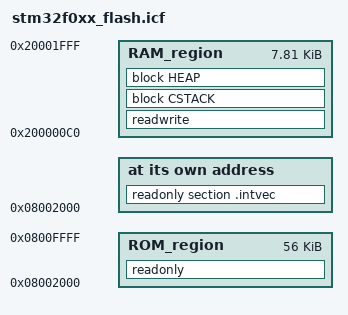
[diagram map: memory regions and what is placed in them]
/*-Specials-*/
define symbol __ICFEDIT_intvec_start__ = 0x08002000;
/*-Memory Regions-*/
/* The first part in flash is reserved for OpenBLT */
define symbol __ICFEDIT_region_ROM_start__ = 0x08002000 ;
define symbol __ICFEDIT_region_ROM_end__   = 0x0800FFFF;
/* The first 192 bytes in RAM are reserved for OpenBLT. Right before
 * starting this program, OpenBLT copies our interrupt vector table
 * to the start of RAM and remaps the RAM to also appear at address 
 * 0x00000000.
 */
define symbol __ICFEDIT_region_RAM_start__ = 0x200000C0;
define symbol __ICFEDIT_region_RAM_end__   = 0x20001FFF;
/*-Sizes-*/
define symbol __ICFEDIT_size_cstack__ = 0x400;
define symbol __ICFEDIT_size_heap__   = 0x200;


define memory mem with size = 4G;
define region ROM_region   = mem:[from __ICFEDIT_region_ROM_start__   to __ICFEDIT_region_ROM_end__];
define region RAM_region   = mem:[from __ICFEDIT_region_RAM_start__   to __ICFEDIT_region_RAM_end__];
export symbol __ICFEDIT_region_RAM_start__;
export symbol __ICFEDIT_region_RAM_end__;
define block CSTACK    with alignment = 8, size = __ICFEDIT_size_cstack__   { };
define block HEAP      with alignment = 8, size = __ICFEDIT_size_heap__     { };

initialize by copy { readwrite };
do not initialize  { section .noinit };

place at address mem:__ICFEDIT_intvec_start__ { readonly section .intvec };

place in ROM_region   { readonly };
place in RAM_region   { readwrite,
                        block CSTACK, block HEAP };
